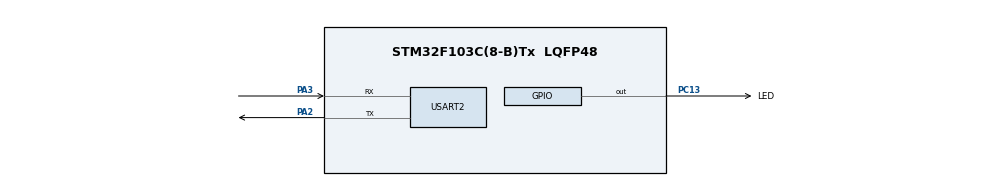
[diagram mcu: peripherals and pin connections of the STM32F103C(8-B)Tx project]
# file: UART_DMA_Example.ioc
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Dma.Request0=USART2_RX
Dma.USART2_RX.0.Direction=DMA_PERIPH_TO_MEMORY
Dma.USART2_RX.0.Instance=DMA1_Channel6
Dma.USART2_RX.0.MemDataAlignment=DMA_MDATAALIGN_BYTE
Dma.USART2_RX.0.MemInc=DMA_MINC_ENABLE
Dma.USART2_RX.0.Mode=DMA_NORMAL
Dma.USART2_RX.0.PeriphDataAlignment=DMA_PDATAALIGN_BYTE
Dma.USART2_RX.0.PeriphInc=DMA_PINC_DISABLE
Dma.USART2_RX.0.Priority=DMA_PRIORITY_LOW
Mcu.Family=STM32F1
Mcu.Name=STM32F103C(8-B)Tx
Mcu.Package=LQFP48
NVIC.DMA1_Channel6_IRQn=true\:0\:0\:false\:false\:true\:false\:true
NVIC.PriorityGroup=NVIC_PRIORITYGROUP_4
NVIC.USART2_IRQn=true\:0\:0\:false\:false\:true\:true\:true
PA13.Mode=Serial_Wire
PA13.Signal=SYS_JTMS-SWDIO
PA14.Mode=Serial_Wire
PA14.Signal=SYS_JTCK-SWCLK
PA2.Mode=Asynchronous
PA2.Signal=USART2_TX
PA3.Mode=Asynchronous
PA3.Signal=USART2_RX
PC13-TAMPER-RTC.GPIO_Label=LED
PC13-TAMPER-RTC.Signal=GPIO_Output
PD0-OSC_IN.Mode=HSE-External-Oscillator
PD0-OSC_IN.Signal=RCC_OSC_IN
PD1-OSC_OUT.Mode=HSE-External-Oscillator
PD1-OSC_OUT.Signal=RCC_OSC_OUT
ProjectManager.HeapSize=0x200
ProjectManager.StackSize=0x400
ProjectManager.TargetToolchain=Makefile
RCC.APB1Freq_Value=8000000
RCC.APB2Freq_Value=8000000
RCC.SYSCLKSource=RCC_SYSCLKSOURCE_HSE
USART2.VirtualMode=VM_ASYNC
board=custom

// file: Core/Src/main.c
/* USER CODE BEGIN Header */
/**
  ******************************************************************************
  * @file           : main.c
  * @brief          : Main program body
  ******************************************************************************
  * @attention
  *
  * <h2><center>&copy; Copyright (c) 2021 STMicroelectronics.
  * All rights reserved.</center></h2>
  *
  * This software component is licensed by ST under BSD 3-Clause license,
  * the "License"; You may not use this file except in compliance with the
  * License. You may obtain a copy of the License at:
  *                        opensource.org/licenses/BSD-3-Clause
  *
  ******************************************************************************
  */
/* USER CODE END Header */
#include "main.h"

/* USER CODE BEGIN Includes */
#include <string.h>
/* USER CODE END Includes */

UART_HandleTypeDef huart2;
DMA_HandleTypeDef hdma_usart2_rx;

void SystemClock_Config(void);
static void MX_GPIO_Init(void);
static void MX_DMA_Init(void);
static void MX_USART2_UART_Init(void);

/* USER CODE BEGIN 0 */
#define RxBuf_SIZE 10
#define MainBuf_SIZE 20

uint8_t RxBuf[RxBuf_SIZE];
uint8_t MainBuf[MainBuf_SIZE];

uint16_t oldPos = 0;
uint16_t newPos = 0;

int isOK = 0;

/* USER CODE END 0 */

int main(void)
{

  /* MCU Configuration--------------------------------------------------------*/

  /* Reset of all peripherals, Initializes the Flash interface and the Systick. */
  HAL_Init();

  /* Configure the system clock */
  SystemClock_Config();

  /* Initialize all configured peripherals */
  MX_GPIO_Init();
  MX_DMA_Init();
  MX_USART2_UART_Init();
  /* USER CODE BEGIN 2 */
  HAL_UARTEx_ReceiveToIdle_DMA(&huart2, RxBuf, RxBuf_SIZE);
  __HAL_DMA_DISABLE_IT(&hdma_usart2_rx, DMA_IT_HT);
  /* USER CODE END 2 */

  /* Infinite loop */
  /* USER CODE BEGIN WHILE */
  uint8_t data[] = "HELLO WORLD123 \r\n";

  while (1)
  {
    /* USER CODE END WHILE */

    /* USER CODE BEGIN 3 */

    // HAL_GPIO_TogglePin(LED_GPIO_Port,LED_Pin);
    // HAL_Delay (5000);
  }
  /* USER CODE END 3 */
}

void SystemClock_Config(void)
{
  RCC_OscInitTypeDef RCC_OscInitStruct = {0};
  RCC_ClkInitTypeDef RCC_ClkInitStruct = {0};

  /** Initializes the RCC Oscillators according to the specified parameters
  * in the RCC_OscInitTypeDef structure.
  */
  RCC_OscInitStruct.OscillatorType = RCC_OSCILLATORTYPE_HSE;
  RCC_OscInitStruct.HSEState = RCC_HSE_ON;
  RCC_OscInitStruct.PLL.PLLState = RCC_PLL_NONE;
  if (HAL_RCC_OscConfig(&RCC_OscInitStruct) != HAL_OK)
  {
    Error_Handler();
  }
  /** Initializes the CPU, AHB and APB buses clocks
  */
  RCC_ClkInitStruct.ClockType = RCC_CLOCKTYPE_HCLK|RCC_CLOCKTYPE_SYSCLK
                              |RCC_CLOCKTYPE_PCLK1|RCC_CLOCKTYPE_PCLK2;
  RCC_ClkInitStruct.SYSCLKSource = RCC_SYSCLKSOURCE_HSE;
  RCC_ClkInitStruct.AHBCLKDivider = RCC_SYSCLK_DIV1;
  RCC_ClkInitStruct.APB1CLKDivider = RCC_HCLK_DIV1;
  RCC_ClkInitStruct.APB2CLKDivider = RCC_HCLK_DIV1;

  if (HAL_RCC_ClockConfig(&RCC_ClkInitStruct, FLASH_LATENCY_0) != HAL_OK)
  {
    Error_Handler();
  }
}

static void MX_USART2_UART_Init(void)
{

  huart2.Instance = USART2;
  huart2.Init.BaudRate = 115200;
  huart2.Init.WordLength = UART_WORDLENGTH_8B;
  huart2.Init.StopBits = UART_STOPBITS_1;
  huart2.Init.Parity = UART_PARITY_NONE;
  huart2.Init.Mode = UART_MODE_TX_RX;
  huart2.Init.HwFlowCtl = UART_HWCONTROL_NONE;
  huart2.Init.OverSampling = UART_OVERSAMPLING_16;
  if (HAL_UART_Init(&huart2) != HAL_OK)
  {
    Error_Handler();
  }

}

static void MX_DMA_Init(void)
{

  /* DMA controller clock enable */
  __HAL_RCC_DMA1_CLK_ENABLE();

  /* DMA interrupt init */
  /* DMA1_Channel6_IRQn interrupt configuration */
  HAL_NVIC_SetPriority(DMA1_Channel6_IRQn, 0, 0);
  HAL_NVIC_EnableIRQ(DMA1_Channel6_IRQn);

}

static void MX_GPIO_Init(void)
{
  GPIO_InitTypeDef GPIO_InitStruct = {0};

  /* GPIO Ports Clock Enable */
  __HAL_RCC_GPIOC_CLK_ENABLE();
  __HAL_RCC_GPIOD_CLK_ENABLE();
  __HAL_RCC_GPIOA_CLK_ENABLE();

  /*Configure GPIO pin Output Level */
  HAL_GPIO_WritePin(LED_GPIO_Port, LED_Pin, GPIO_PIN_RESET);

  /*Configure GPIO pin : LED_Pin */
  GPIO_InitStruct.Pin = LED_Pin;
  GPIO_InitStruct.Mode = GPIO_MODE_OUTPUT_PP;
  GPIO_InitStruct.Pull = GPIO_NOPULL;
  GPIO_InitStruct.Speed = GPIO_SPEED_FREQ_LOW;
  HAL_GPIO_Init(LED_GPIO_Port, &GPIO_InitStruct);

}

/* USER CODE BEGIN 4 */

void HAL_UARTEx_RxEventCallback(UART_HandleTypeDef *huart, uint16_t Size)
{
	if (huart->Instance == USART2)
	{
		oldPos = newPos;  // Update the last position before copying new data

		/* If the data in large and it is about to exceed the buffer size, we have to route it to the start of the buffer
		 * This is to maintain the circular buffer
		 * The old data in the main buffer will be overlapped
		 */
		if (oldPos+Size > MainBuf_SIZE)  // If the current position + new data size is greater than the main buffer
		{
			uint16_t datatocopy = MainBuf_SIZE-oldPos;  // find out how much space is left in the main buffer
			memcpy ((uint8_t *)MainBuf+oldPos, RxBuf, datatocopy);  // copy data in that remaining space

			oldPos = 0;  // point to the start of the buffer
			memcpy ((uint8_t *)MainBuf, (uint8_t *)RxBuf+datatocopy, (Size-datatocopy));  // copy the remaining data
			newPos = (Size-datatocopy);  // update the position
		}

		/* if the current position + new data size is less than the main buffer
		 * we will simply copy the data into the buffer and update the position
		 */
		else
		{
			memcpy ((uint8_t *)MainBuf+oldPos, RxBuf, Size);
			newPos = Size+oldPos;
		}

		/* start the DMA again */
		HAL_UARTEx_ReceiveToIdle_DMA(&huart2, (uint8_t *) RxBuf, RxBuf_SIZE);
		__HAL_DMA_DISABLE_IT(&hdma_usart2_rx, DMA_IT_HT);

	}
  // for(uint16_t i = oldPos; i < newPos; i++){
    HAL_UART_Transmit(&huart2,MainBuf,sizeof(MainBuf),100);
  // }

}

/* USER CODE END 4 */

void Error_Handler(void)
{
  __disable_irq();
  while (1)
  {
  }
}

/************************ (C) COPYRIGHT STMicroelectronics *****END OF FILE****/
